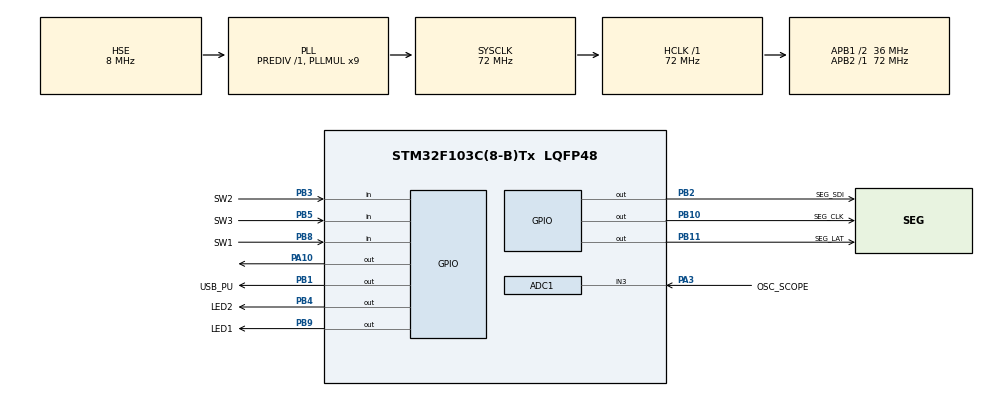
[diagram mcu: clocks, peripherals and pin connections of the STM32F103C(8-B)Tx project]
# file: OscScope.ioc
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ADC1.Channel-1\#ChannelRegularConversion=ADC_CHANNEL_3
ADC1.ContinuousConvMode=ENABLE
ADC1.NbrOfConversionFlag=1
ADC1.Rank-1\#ChannelRegularConversion=1
ADC1.SamplingTime-1\#ChannelRegularConversion=ADC_SAMPLETIME_239CYCLES_5
ADC1.master=1
Dma.ADC1.0.Direction=DMA_PERIPH_TO_MEMORY
Dma.ADC1.0.Instance=DMA1_Channel1
Dma.ADC1.0.MemDataAlignment=DMA_MDATAALIGN_HALFWORD
Dma.ADC1.0.MemInc=DMA_MINC_ENABLE
Dma.ADC1.0.Mode=DMA_CIRCULAR
Dma.ADC1.0.PeriphDataAlignment=DMA_PDATAALIGN_HALFWORD
Dma.ADC1.0.PeriphInc=DMA_PINC_DISABLE
Dma.ADC1.0.Priority=DMA_PRIORITY_LOW
Dma.Request0=ADC1
Mcu.Family=STM32F1
Mcu.Name=STM32F103C(8-B)Tx
Mcu.Package=LQFP48
NVIC.DMA1_Channel1_IRQn=true\:0\:0\:false\:false\:true\:false\:true
NVIC.PriorityGroup=NVIC_PRIORITYGROUP_4
PA0-WKUP.GPIO_Label=POT1
PA0-WKUP.Signal=ADCx_IN0
PA1.GPIO_Label=POT2
PA1.Signal=ADCx_IN1
PA10.PinState=GPIO_PIN_SET
PA10.Signal=GPIO_Output
PA11.Signal=USB_DM
PA12.Signal=USB_DP
PA13.GPIO_Label=SWDIO
PA13.Mode=Serial_Wire
PA13.Signal=SYS_JTMS-SWDIO
PA14.GPIO_Label=SWCLK
PA14.Mode=Serial_Wire
PA14.Signal=SYS_JTCK-SWCLK
PA15.GPIO_Label=BUZ
PA15.Signal=S_TIM2_CH1_ETR
PA2.GPIO_Label=TX2
PA2.Signal=USART2_TX
PA3.GPIO_Label=OSC_SCOPE
PA3.Signal=ADCx_IN3
PA4.GPIO_Label=POT3
PA4.Signal=ADCx_IN4
PA5.GPIO_Label=TEMP
PA5.Signal=ADCx_IN5
PA6.GPIO_Label=PWM_R
PA6.Signal=S_TIM3_CH1
PA7.GPIO_Label=PWM_G
PA7.Signal=S_TIM3_CH2
PA8.GPIO_Label=PWM_P
PA8.Signal=S_TIM1_CH1
PB0.GPIO_Label=PWM_B
PB0.Signal=S_TIM3_CH3
PB1.GPIO_Label=USB_PU
PB1.GPIO_Speed=GPIO_SPEED_FREQ_HIGH
PB1.PinState=GPIO_PIN_RESET
PB1.Signal=GPIO_Output
PB10.GPIO_Label=SEG_CLK
PB10.GPIO_ModeDefaultOutputPP=GPIO_MODE_OUTPUT_OD
PB10.GPIO_PuPd=GPIO_NOPULL
PB10.GPIO_Speed=GPIO_SPEED_FREQ_HIGH
PB10.PinState=GPIO_PIN_RESET
PB10.Signal=GPIO_Output
PB11.GPIO_Label=SEG_LAT
PB11.GPIO_ModeDefaultOutputPP=GPIO_MODE_OUTPUT_OD
PB11.GPIO_PuPd=GPIO_NOPULL
PB11.GPIO_Speed=GPIO_SPEED_FREQ_HIGH
PB11.PinState=GPIO_PIN_RESET
PB11.Signal=GPIO_Output
PB13.GPIO_Label=PWM_N
PB13.Signal=TIM1_CH1N
PB2.GPIO_Label=SEG_SDI
PB2.GPIO_ModeDefaultOutputPP=GPIO_MODE_OUTPUT_OD
PB2.GPIO_PuPd=GPIO_NOPULL
PB2.GPIO_Speed=GPIO_SPEED_FREQ_HIGH
PB2.PinState=GPIO_PIN_RESET
PB2.Signal=GPIO_Output
PB3.GPIO_Label=SW2
PB3.Signal=GPIO_Input
PB4.GPIO_Label=LED2
PB4.GPIO_Speed=GPIO_SPEED_FREQ_HIGH
PB4.PinState=GPIO_PIN_RESET
PB4.Signal=GPIO_Output
PB5.GPIO_Label=SW3
PB5.Signal=GPIO_Input
PB6.GPIO_Label=ROT_A
PB6.Signal=S_TIM4_CH1
PB7.GPIO_Label=ROT_B
PB7.Signal=S_TIM4_CH2
PB8.GPIO_Label=SW1
PB8.Signal=GPIO_Input
PB9.GPIO_Label=LED1
PB9.GPIO_Speed=GPIO_SPEED_FREQ_HIGH
PB9.PinState=GPIO_PIN_RESET
PB9.Signal=GPIO_Output
PD0-OSC_IN.GPIO_Label=OSC_IN
PD0-OSC_IN.Mode=HSE-External-Oscillator
PD0-OSC_IN.Signal=RCC_OSC_IN
PD1-OSC_OUT.GPIO_Label=OSC_OUT
PD1-OSC_OUT.Mode=HSE-External-Oscillator
PD1-OSC_OUT.Signal=RCC_OSC_OUT
ProjectManager.HeapSize=0x200
ProjectManager.StackSize=0x400
ProjectManager.TargetToolchain=MDK-ARM V5.27
RCC.ADCPresc=RCC_ADCPCLK2_DIV6
RCC.AHBFreq_Value=72000000
RCC.APB1CLKDivider=RCC_HCLK_DIV2
RCC.APB1Freq_Value=36000000
RCC.APB1TimFreq_Value=72000000
RCC.APB2Freq_Value=72000000
RCC.APB2TimFreq_Value=72000000
RCC.HCLKFreq_Value=72000000
RCC.PLLMUL=RCC_PLL_MUL9
RCC.PLLSourceVirtual=RCC_PLLSOURCE_HSE
RCC.SYSCLKFreq_VALUE=72000000
RCC.SYSCLKSource=RCC_SYSCLKSOURCE_PLLCLK
RCC.USBFreq_Value=48000000
RCC.USBPrescaler=RCC_USBCLKSOURCE_PLL_DIV1_5
SH.ADCx_IN0.0=ADC1_IN0
SH.ADCx_IN1.0=ADC1_IN1
SH.ADCx_IN3.0=ADC1_IN3,IN3
SH.ADCx_IN4.0=ADC1_IN4
SH.ADCx_IN5.0=ADC1_IN5
SH.S_TIM1_CH1.0=TIM1_CH1
SH.S_TIM2_CH1_ETR.0=TIM2_CH1
SH.S_TIM3_CH1.0=TIM3_CH1
SH.S_TIM3_CH2.0=TIM3_CH2
SH.S_TIM3_CH3.0=TIM3_CH3
SH.S_TIM4_CH1.0=TIM4_CH1
SH.S_TIM4_CH2.0=TIM4_CH2
board=custom

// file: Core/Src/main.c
/* USER CODE BEGIN Header */
/**
  ******************************************************************************
  * @file           : main.c
  * @brief          : Main program body
  ******************************************************************************
  * @attention
  *
  * Copyright (c) 2022 STMicroelectronics.
  * All rights reserved.
  *
  * This software is licensed under terms that can be found in the LICENSE file
  * in the root directory of this software component.
  * If no LICENSE file comes with this software, it is provided AS-IS.
  *
  ******************************************************************************
  */
/* USER CODE END Header */
#include "main.h"
#include "adc.h"
#include "dma.h"
#include "gpio.h"

void SystemClock_Config(void);

/* USER CODE BEGIN 0 */
uint16_t raw[64];
float v;
/* USER CODE END 0 */

int main(void)
{

  /* MCU Configuration--------------------------------------------------------*/

  /* Reset of all peripherals, Initializes the Flash interface and the Systick. */
  HAL_Init();

  /* Configure the system clock */
  SystemClock_Config();

  /* Initialize all configured peripherals */
  MX_GPIO_Init();
  MX_DMA_Init();
  MX_ADC1_Init();
  /* USER CODE BEGIN 2 */
	HAL_ADC_Start_DMA(&hadc1, (uint32_t *)raw, 64);
  /* USER CODE END 2 */

  /* Infinite loop */
  while (1)
  {

    /* USER CODE BEGIN 3 */
		uint32_t accum = 0;
		for(int i = 0; i < 64; i++)
		{
			accum += raw[i];
		}
		accum >>= 6;
		v = 3.3 * ((float)accum) / 4096;
  }
  /* USER CODE END 3 */
}

void SystemClock_Config(void)
{
  RCC_OscInitTypeDef RCC_OscInitStruct = {0};
  RCC_ClkInitTypeDef RCC_ClkInitStruct = {0};
  RCC_PeriphCLKInitTypeDef PeriphClkInit = {0};

  /** Initializes the RCC Oscillators according to the specified parameters
  * in the RCC_OscInitTypeDef structure.
  */
  RCC_OscInitStruct.OscillatorType = RCC_OSCILLATORTYPE_HSE;
  RCC_OscInitStruct.HSEState = RCC_HSE_ON;
  RCC_OscInitStruct.HSEPredivValue = RCC_HSE_PREDIV_DIV1;
  RCC_OscInitStruct.HSIState = RCC_HSI_ON;
  RCC_OscInitStruct.PLL.PLLState = RCC_PLL_ON;
  RCC_OscInitStruct.PLL.PLLSource = RCC_PLLSOURCE_HSE;
  RCC_OscInitStruct.PLL.PLLMUL = RCC_PLL_MUL9;
  if (HAL_RCC_OscConfig(&RCC_OscInitStruct) != HAL_OK)
  {
    Error_Handler();
  }
  /** Initializes the CPU, AHB and APB buses clocks
  */
  RCC_ClkInitStruct.ClockType = RCC_CLOCKTYPE_HCLK|RCC_CLOCKTYPE_SYSCLK
                              |RCC_CLOCKTYPE_PCLK1|RCC_CLOCKTYPE_PCLK2;
  RCC_ClkInitStruct.SYSCLKSource = RCC_SYSCLKSOURCE_PLLCLK;
  RCC_ClkInitStruct.AHBCLKDivider = RCC_SYSCLK_DIV1;
  RCC_ClkInitStruct.APB1CLKDivider = RCC_HCLK_DIV2;
  RCC_ClkInitStruct.APB2CLKDivider = RCC_HCLK_DIV1;

  if (HAL_RCC_ClockConfig(&RCC_ClkInitStruct, FLASH_LATENCY_2) != HAL_OK)
  {
    Error_Handler();
  }
  PeriphClkInit.PeriphClockSelection = RCC_PERIPHCLK_ADC;
  PeriphClkInit.AdcClockSelection = RCC_ADCPCLK2_DIV6;
  if (HAL_RCCEx_PeriphCLKConfig(&PeriphClkInit) != HAL_OK)
  {
    Error_Handler();
  }
}

void Error_Handler(void)
{
  __disable_irq();
  while (1)
  {
  }
}
